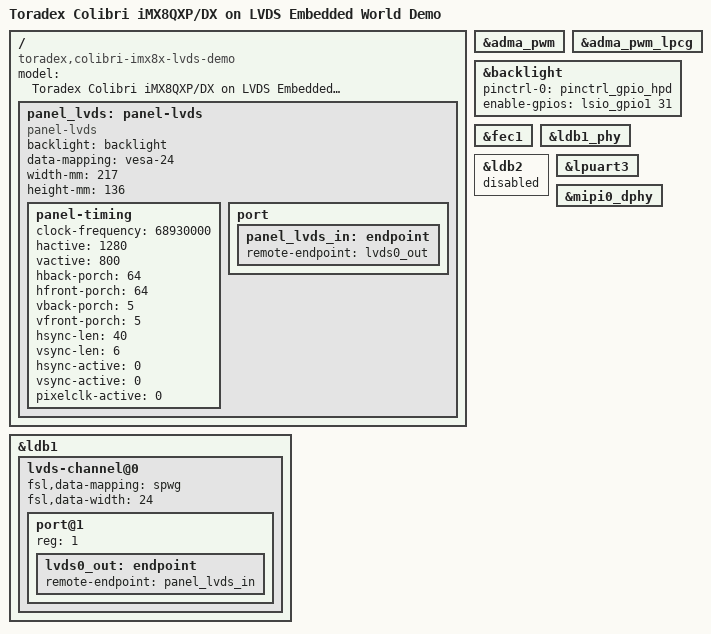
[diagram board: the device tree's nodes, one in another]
// SPDX-License-Identifier: GPL-2.0+ OR X11
/*
 * Copyright 2018-2020 Toradex
 */

/dts-v1/;

#include "imx8qxp-colibri.dtsi"

/ {
	model = "Toradex Colibri iMX8QXP/DX on LVDS Embedded World Demo";
	compatible = "toradex,colibri-imx8x-lvds-demo",
		     "toradex,colibri-imx8x",
		     "fsl,imx8qxp";

	panel_lvds: panel-lvds {
		compatible = "panel-lvds";
		backlight = <&backlight>;
		data-mapping = "vesa-24";
		width-mm = <217>;
		height-mm = <136>;

		status = "okay";

		panel-timing {
			clock-frequency = <68930000>;
			hactive = <1280>;
			vactive = <800>;
			hback-porch = <64>;
			hfront-porch = <64>;
			vback-porch = <5>;
			vfront-porch = <5>;
			hsync-len = <40>;
			vsync-len = <6>;
			hsync-active = <0>;
			vsync-active = <0>;
			pixelclk-active = <0>;
		};

		port {
			panel_lvds_in: endpoint {
				remote-endpoint = <&lvds0_out>;
			};
		};
	};
};

&adma_pwm {
	status = "okay";
};

&adma_pwm_lpcg {
	status = "okay";
};

&backlight {
	pinctrl-0 = <&pinctrl_gpio_hpd>;
	enable-gpios = <&lsio_gpio1 31 GPIO_ACTIVE_HIGH>; /* Colibri BL_ON */
	status = "okay";
};

/* Colibri FastEthernet */
&fec1 {
	status = "okay";
};

&ldb1 {
	status = "okay";

	lvds-channel@0 {
		 fsl,data-mapping = "spwg";
		 fsl,data-width = <24>;
		 status = "okay";

		 port@1 {
			  reg = <1>;

			  lvds0_out: endpoint {
				   remote-endpoint = <&panel_lvds_in>;
			  };
		 };
	};
};

&ldb1_phy {
	status = "okay";
};

&ldb2 {
	status = "disabled";
};

/* Colibri UART_A */
&lpuart3 {
	status= "okay";
};

&mipi0_dphy {
	status = "okay";
};

